VERSION "BEACON reference pack v1"

NS_ :

BS_:

BU_: BMS VCU

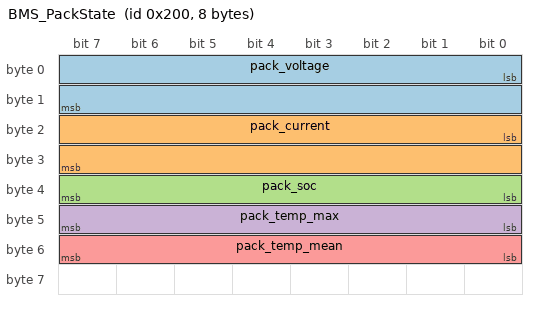
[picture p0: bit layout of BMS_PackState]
BO_ 512 BMS_PackState: 8 BMS
 SG_ pack_voltage : 0|16@1+ (0.01,0) [0|655.35] "V" VCU
 SG_ pack_current : 16|16@1- (0.1,0) [-3276.8|3276.7] "A" VCU
 SG_ pack_soc : 32|8@1+ (0.5,0) [0|100] "%" VCU
 SG_ pack_temp_max : 40|8@1- (1,-40) [-40|215] "degC" VCU
 SG_ pack_temp_mean : 48|8@1- (1,-40) [-40|215] "degC" VCU

CM_ BO_ 512 "Aggregate pack state reported once per 100 ms.";
CM_ SG_ 512 pack_current "Negative is discharge, matching the unified schema.";
CM_ SG_ 512 pack_temp_mean "Mean of cell thermistors.";
